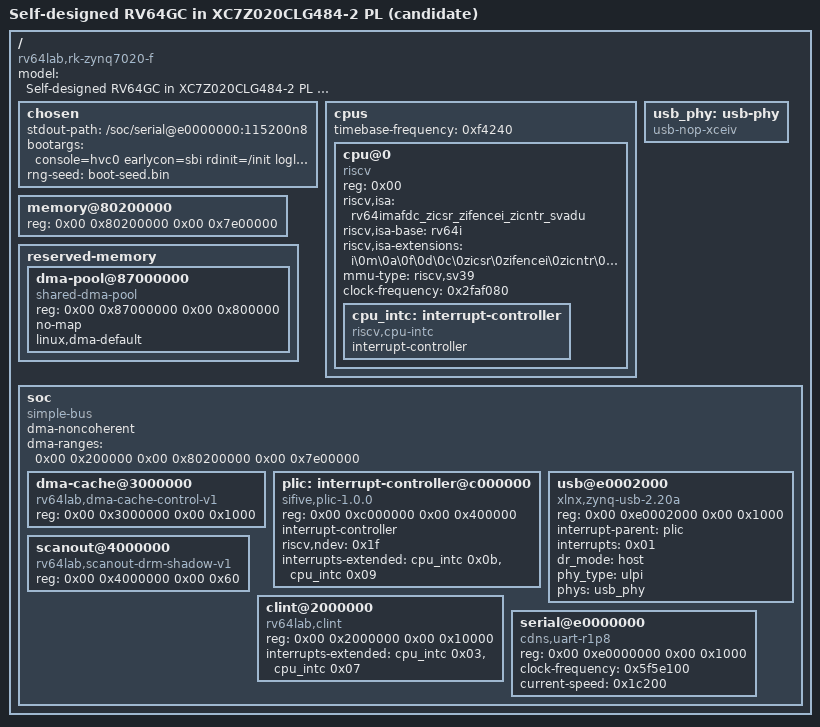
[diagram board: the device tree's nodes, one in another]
// Derived from the DT loaded on the real R113 board boot.
// Fresh boot-seed.bin is generated by tools/make_dtb.py; never reuse a public seed.
/dts-v1/;

/ {
	#address-cells = <0x02>;
	#size-cells = <0x02>;
	compatible = "rv64lab,rk-zynq7020-f";
	model = "Self-designed RV64GC in XC7Z020CLG484-2 PL (candidate)";

	chosen {
		stdout-path = "/soc/serial@e0000000:115200n8";
		bootargs = "console=hvc0 earlycon=sbi rdinit=/init loglevel=7 panic=-1 random.trust_bootloader=on";
		rng-seed = /incbin/("boot-seed.bin");
	};

	cpus {
		#address-cells = <0x01>;
		#size-cells = <0x00>;
		timebase-frequency = <0xf4240>;

		cpu@0 {
			device_type = "cpu";
			reg = <0x00>;
			status = "okay";
			compatible = "riscv";
			riscv,isa = "rv64imafdc_zicsr_zifencei_zicntr_svadu";
			riscv,isa-base = "rv64i";
			riscv,isa-extensions = "i\0m\0a\0f\0d\0c\0zicsr\0zifencei\0zicntr\0svadu";
			mmu-type = "riscv,sv39";
			clock-frequency = <0x2faf080>;

			cpu_intc: interrupt-controller {
				#interrupt-cells = <0x01>;
				#address-cells = <0x00>;
				compatible = "riscv,cpu-intc";
				interrupt-controller;
				phandle = <0x01>;
			};
		};
	};

	memory@80200000 {
		device_type = "memory";
		reg = <0x00 0x80200000 0x00 0x7e00000>;
	};

	reserved-memory {
		#address-cells = <0x02>;
		#size-cells = <0x02>;
		ranges;

		dma-pool@87000000 {
			compatible = "shared-dma-pool";
			reg = <0x00 0x87000000 0x00 0x800000>;
			no-map;
			linux,dma-default;
		};
	};

	usb_phy: usb-phy {
		compatible = "usb-nop-xceiv";
		#phy-cells = <0x00>;
		phandle = <0x03>;
	};

	soc {
		#address-cells = <0x02>;
		#size-cells = <0x02>;
		compatible = "simple-bus";
		ranges;
		dma-noncoherent;
		dma-ranges = <0x00 0x200000 0x00 0x80200000 0x00 0x7e00000>;

		dma-cache@3000000 {
			compatible = "rv64lab,dma-cache-control-v1";
			reg = <0x00 0x3000000 0x00 0x1000>;
		};

		plic: interrupt-controller@c000000 {
			compatible = "sifive,plic-1.0.0";
			reg = <0x00 0xc000000 0x00 0x400000>;
			#interrupt-cells = <0x01>;
			#address-cells = <0x00>;
			interrupt-controller;
			riscv,ndev = <0x1f>;
			interrupts-extended = <&cpu_intc 0x0b &cpu_intc 0x09>;
			phandle = <0x02>;
		};

		usb@e0002000 {
			compatible = "xlnx,zynq-usb-2.20a";
			reg = <0x00 0xe0002000 0x00 0x1000>;
			interrupt-parent = <&plic>;
			interrupts = <0x01>;
			dr_mode = "host";
			phy_type = "ulpi";
			phys = <&usb_phy>;
			status = "okay";
		};

		scanout@4000000 {
			compatible = "rv64lab,scanout-drm-shadow-v1";
			reg = <0x00 0x4000000 0x00 0x60>;
			status = "okay";
		};

		clint@2000000 {
			compatible = "rv64lab,clint\0sifive,clint0";
			reg = <0x00 0x2000000 0x00 0x10000>;
			interrupts-extended = <&cpu_intc 0x03 &cpu_intc 0x07>;
		};

		serial@e0000000 {
			compatible = "cdns,uart-r1p8";
			reg = <0x00 0xe0000000 0x00 0x1000>;
			clock-frequency = <0x5f5e100>;
			current-speed = <0x1c200>;
			status = "okay";
		};
	};
};
